# WBZ450 register map
Vendor: Microchip
Registers are 32-bit, read-write, reset 0x0 unless marked. A register's access mark holds for its fields unless they carry their own. Addresses are absolute, and some are shared; only a register's first bit layout is shown; [hi:lo] are bit positions; {n}, {i} and the like mark numbered series; 'fields as' and 'values as' point back to an identical list.

## CCL
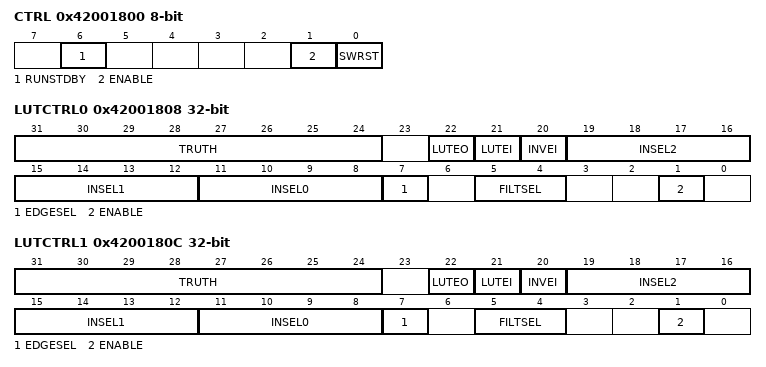
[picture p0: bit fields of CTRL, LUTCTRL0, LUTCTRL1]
0x42001800 CTRL 8-bit
  [6] RUNSTDBY — Run in Standby
    0=DISABLE (Generic clock is not required in standby sleep mode); 1=ENABLE (Generic clock is required in standby sleep mode)
  [1] ENABLE
    0=DISABLE (The peripheral is disabled); 1=ENABLE (The peripheral is enabled)
  [0] SWRST — Software Reset
    0=DISABLE (The peripheral is not reset); 1=ENABLE (The peripheral is reset)
0x42001804 SEQCTRL0 8-bit
  [3:0] SEQSEL — Sequential Selection
    0=DISABLE (Sequential logic is disabled); 1=DFF (D flip flop); 2=JK (JK flip flop); 3=LATCH (D latch); 4=RS (RS latch)
0x42001805 SEQCTRL1 8-bit
  fields as SEQCTRL0
0x42001808 LUTCTRL0
  [31:24] TRUTH — Truth Value
  [22] LUTEO — LUT Event Output Enable
    0=DISABLE (LUT event output is disabled); 1=ENABLE (LUT event output is enabled)
  [21] LUTEI — LUT Event Input Enable
    0=DISABLE (LUT incoming event is disabled); 1=ENABLE (LUT incoming event is enabled)
  [20] INVEI — Inverted Event Input Enable
    0=DISABLE (Incoming event is not inverted); 1=ENABLE (Incoming event is inverted)
  [19:16] INSEL2 — Input Selection 2
    0=MASK (Masked input); 1=FEEDBACK (Feedback input source); 2=LINK (Linked LUT input source); 3=EVENT (Event input source); 4=IO (I/O pin input source); 5=AC (AC input source); 6=TC (TC input source); 7=ALTTC (Alternate TC input source); 8=TCC (TCC input source); 9=SERCOM (SERCOM input source)
  [15:12] INSEL1 — Input Selection 1
    values as INSEL2
  [11:8] INSEL0 — Input Selection 0
    values as INSEL2
  [7] EDGESEL — Edge Selection
    0=DISABLE (Edge detector is disabled); 1=ENABLE (Edge detector is enabled)
  [5:4] FILTSEL — Filter Selection
    0=DISABLE (Filter disabled); 1=SYNCH (Synchronizer enabled); 2=FILTER (Filter enabled)
  [1] ENABLE — LUT Enable
    0=DISABLE (LUT block is disabled); 1=ENABLE (LUT block is enabled)
0x4200180C LUTCTRL1
  fields as LUTCTRL0

## AC
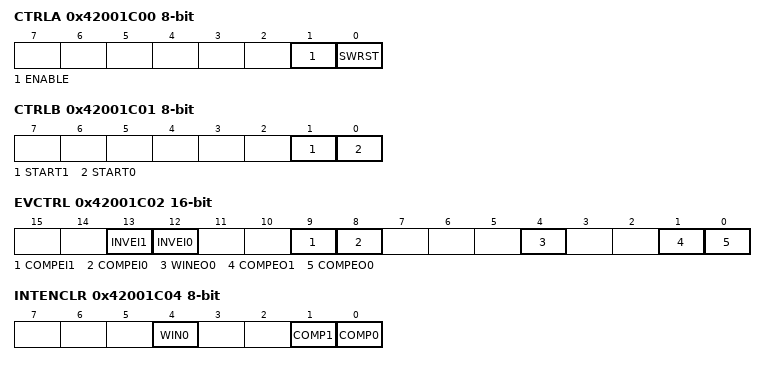
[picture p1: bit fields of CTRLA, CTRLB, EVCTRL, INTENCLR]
0x42001C00 CTRLA 8-bit
  [1] ENABLE
  [0] SWRST — Software Reset
0x42001C01 CTRLB 8-bit wo
  [1] START1 — Comparator 1 Start Comparison
  [0] START0 — Comparator 0 Start Comparison
0x42001C02 EVCTRL 16-bit
  [13] INVEI1 — Comparator 1 Input Event Invert Enable
  [12] INVEI0 — Comparator 0 Input Event Invert Enable
  [9] COMPEI1 — Comparator 1 Event Input Enable
  [8] COMPEI0 — Comparator 0 Event Input Enable
  [4] WINEO0 — Window 0 Event Output Enable
  [1] COMPEO1 — Comparator 1 Event Output Enable
  [0] COMPEO0 — Comparator 0 Event Output Enable
0x42001C04 INTENCLR 8-bit
  [4] WIN0 — Window 0 Interrupt Enable
  [1] COMP1 — Comparator 1 Interrupt Enable
  [0] COMP0 — Comparator 0 Interrupt Enable
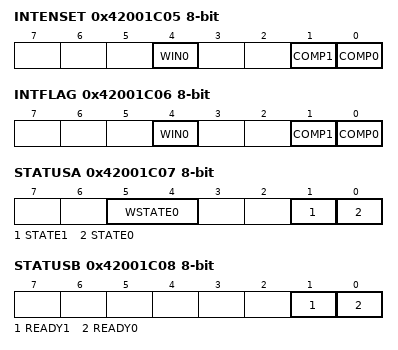
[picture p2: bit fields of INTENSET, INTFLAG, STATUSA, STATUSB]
0x42001C05 INTENSET 8-bit
  fields as INTENCLR
0x42001C06 INTFLAG 8-bit
  [4] WIN0 — Window 0
  [1] COMP1 — Comparator 1
  [0] COMP0 — Comparator 0
0x42001C07 STATUSA 8-bit ro
  [5:4] WSTATE0 — Window 0 Current State
    0=ABOVE (Signal is above window); 1=INSIDE (Signal is inside window); 2=BELOW (Signal is below window)
  [1] STATE1 — Comparator 1 Current State
  [0] STATE0 — Comparator 0 Current State
0x42001C08 STATUSB 8-bit ro
  [1] READY1 — Comparator 1 Ready
  [0] READY0 — Comparator 0 Ready
0x42001C09 DBGCTRL 8-bit
  [0] DBGRUN — Debug Run
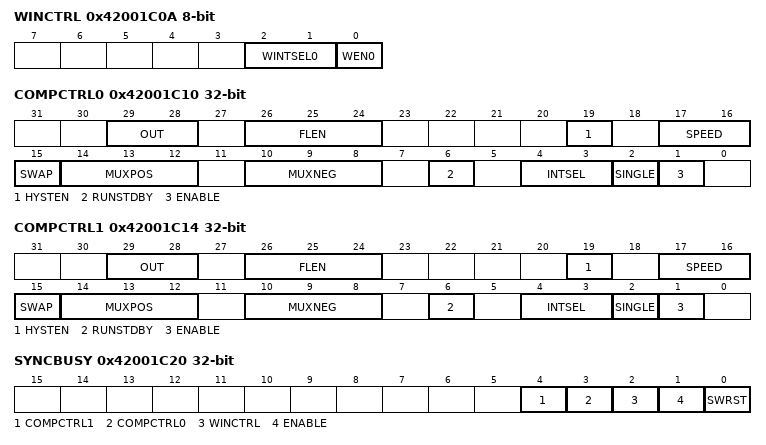
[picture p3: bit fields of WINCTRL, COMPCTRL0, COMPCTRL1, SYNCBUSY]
0x42001C0A WINCTRL 8-bit
  [2:1] WINTSEL0 — Window 0 Interrupt Selection
    0=ABOVE (Interrupt on signal above window); 1=INSIDE (Interrupt on signal inside window); 2=BELOW (Interrupt on signal below window); 3=OUTSIDE (Interrupt on signal outside window)
  [0] WEN0 — Window 0 Mode Enable
0x42001C0C SCALER0 8-bit
  [5:0] VALUE — Scaler Value
0x42001C0D SCALER1 8-bit
  [5:0] VALUE — Scaler Value
0x42001C10 COMPCTRL0
  [29:28] OUT — Output
    0=OFF (The output of COMPn is not routed to the COMPn I/O port); 1=ASYNC (The asynchronous output of COMPn is routed to the COMPn I/O port); 2=SYNC (The synchronous output (including filtering) of COMPn is routed to the COMPn I/O port)
  [26:24] FLEN — Filter Length
    0=OFF (No filtering); 1=MAJ3 (3-bit majority function (2 of 3)); 2=MAJ5 (5-bit majority function (3 of 5))
  [19] HYSTEN — Hysteresis Enable
  [17:16] SPEED
  [15] SWAP — Swap Inputs and Invert
  [14:12] MUXPOS — Positive Input Mux Selection
    {v}=PIN{v} (I/O pin {v}) (v=0..3); 4=VSCALE (VDD Scaler)
  [10:8] MUXNEG — Negative Input Mux Selection
    {v}=PIN{v} (I/O pin {v}) (v=0..3); 4=GND (Ground); 5=VSCALE (VDD scaler); 6=BANDGAP (Internal bandgap voltage); 7=DAC (DAC output)
  [6] RUNSTDBY — Run in Standby
  [4:3] INTSEL — Interrupt Selection
    0=TOGGLE (Interrupt on comparator output toggle); 1=RISING (Interrupt on comparator output rising); 2=FALLING (Interrupt on comparator output falling); 3=EOC (Interrupt on end of comparison (single-shot mode only))
  [2] SINGLE — Single-Shot Mode
  [1] ENABLE
0x42001C14 COMPCTRL1
  fields as COMPCTRL0
0x42001C20 SYNCBUSY ro
  [4] COMPCTRL1 — COMPCTRL 1 Synchronization Busy
  [3] COMPCTRL0 — COMPCTRL 0 Synchronization Busy
  [2] WINCTRL — WINCTRL Synchronization Busy
  [1] ENABLE — Enable Synchronization Busy
  [0] SWRST — Software Reset Synchronization Busy
0x42001C24 CALIB 16-bit reset 0x101
  [1:0] BIAS0 — COMP0/1 Bias Scaling
